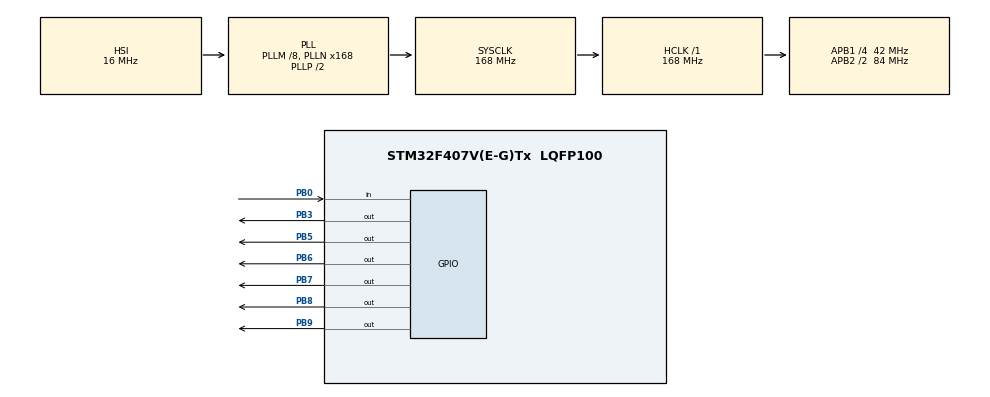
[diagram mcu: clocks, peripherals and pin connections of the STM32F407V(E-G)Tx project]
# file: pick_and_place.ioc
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Mcu.Family=STM32F4
Mcu.Name=STM32F407V(E-G)Tx
Mcu.Package=LQFP100
NVIC.PriorityGroup=NVIC_PRIORITYGROUP_4
PA13.Mode=Serial_Wire
PA13.Signal=SYS_JTMS-SWDIO
PA14.Mode=Serial_Wire
PA14.Signal=SYS_JTCK-SWCLK
PB0.Signal=GPIO_Input
PB3.Signal=GPIO_Output
PB5.Signal=GPIO_Output
PB6.Signal=GPIO_Output
PB7.Signal=GPIO_Output
PB8.Signal=GPIO_Output
PB9.Signal=GPIO_Output
PH0-OSC_IN.Mode=HSE-External-Oscillator
PH0-OSC_IN.Signal=RCC_OSC_IN
PH1-OSC_OUT.Mode=HSE-External-Oscillator
PH1-OSC_OUT.Signal=RCC_OSC_OUT
ProjectManager.HeapSize=0x200
ProjectManager.StackSize=0x400
ProjectManager.TargetToolchain=STM32CubeIDE
RCC.48MHZClocksFreq_Value=84000000
RCC.AHBFreq_Value=168000000
RCC.APB1CLKDivider=RCC_HCLK_DIV4
RCC.APB1Freq_Value=42000000
RCC.APB1TimFreq_Value=84000000
RCC.APB2CLKDivider=RCC_HCLK_DIV2
RCC.APB2Freq_Value=84000000
RCC.APB2TimFreq_Value=168000000
RCC.CortexFreq_Value=168000000
RCC.HCLKFreq_Value=168000000
RCC.HSE_VALUE=25000000
RCC.HSI_VALUE=16000000
RCC.LSE_VALUE=32768
RCC.PLLM=8
RCC.PLLN=168
RCC.SYSCLKFreq_VALUE=168000000
RCC.SYSCLKSource=RCC_SYSCLKSOURCE_PLLCLK
RCC.VCOOutputFreq_Value=336000000
board=custom

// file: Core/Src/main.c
/* USER CODE BEGIN Header */
/**
  ******************************************************************************
  * @file           : main.c
  * @brief          : Main program body
  ******************************************************************************
  * @attention
  *
  * Copyright (c) 2022 STMicroelectronics.
  * All rights reserved.
  *
  * This software is licensed under terms that can be found in the LICENSE file
  * in the root directory of this software component.
  * If no LICENSE file comes with this software, it is provided AS-IS.
  *
  ******************************************************************************
  */
/* USER CODE END Header */
#include "main.h"
#include <stdio.h>
#include <string.h>

/* USER CODE BEGIN Includes */

#define Relay_1_ON HAL_GPIO_WritePin(GPIOB, GPIO_PIN_3, GPIO_PIN_RESET)
#define Relay_1_OFF HAL_GPIO_WritePin(GPIOB, GPIO_PIN_3, GPIO_PIN_SET)

#define Relay_2_ON HAL_GPIO_WritePin(GPIOB, GPIO_PIN_5, GPIO_PIN_RESET)
#define Relay_2_OFF HAL_GPIO_WritePin(GPIOB, GPIO_PIN_5, GPIO_PIN_SET)

#define Relay_3_ON HAL_GPIO_WritePin(GPIOB, GPIO_PIN_6, GPIO_PIN_RESET)
#define Relay_3_OFF HAL_GPIO_WritePin(GPIOB, GPIO_PIN_6, GPIO_PIN_SET)

#define Relay_4_ON HAL_GPIO_WritePin(GPIOB, GPIO_PIN_7, GPIO_PIN_RESET)
#define Relay_4_OFF HAL_GPIO_WritePin(GPIOB, GPIO_PIN_7, GPIO_PIN_SET)

#define SUCTION_ON HAL_GPIO_WritePin(GPIOB, GPIO_PIN_8, GPIO_PIN_RESET)
#define SUCTION_OFF HAL_GPIO_WritePin(GPIOB, GPIO_PIN_8, GPIO_PIN_SET)

/* USER CODE END Includes */

void SystemClock_Config(void);
static void MX_GPIO_Init(void);

void goright()
{
	Relay_1_ON;
	Relay_2_OFF;
}

void goleft()
{
	Relay_1_OFF;
	Relay_2_ON;
}

void go_up()
{
	Relay_3_ON;
	Relay_4_OFF;
}

void go_down()
{
	Relay_3_OFF;
	Relay_4_ON;
}

void initialization()
{
	goright();
	HAL_GPIO_WritePin(GPIOB, GPIO_PIN_9, GPIO_PIN_SET);
	go_up();
	HAL_Delay(5000);
}

void turnoff_init()
{
	Relay_1_OFF;
	Relay_2_OFF;
	Relay_3_OFF;
	Relay_4_OFF;
	HAL_GPIO_WritePin(GPIOB, GPIO_PIN_9, GPIO_PIN_SET);
}

void turnoff(){
	Relay_1_OFF;
	Relay_2_OFF;
	Relay_3_OFF;
	Relay_4_OFF;
}
int main(void)
{

  /* MCU Configuration--------------------------------------------------------*/

  /* Reset of all peripherals, Initializes the Flash interface and the Systick. */
  HAL_Init();

  /* Configure the system clock */
  SystemClock_Config();

  /* Initialize all configured peripherals */
  MX_GPIO_Init();
  /* USER CODE BEGIN 2 */
initialization();
turnoff_init();
  /* USER CODE END 2 */

  /* Infinite loop */
  while (1)
  {

   if ((HAL_GPIO_ReadPin(GPIOB, GPIO_PIN_0)==GPIO_PIN_SET))
   {
	   go_down(); // coming down R3 off, R4 On
	   HAL_Delay(3000);
	   turnoff();
	   HAL_GPIO_WritePin(GPIOB, GPIO_PIN_9, GPIO_PIN_RESET); //suction on
	   go_up(); //Go Up, R3 On, R4 off
	   HAL_Delay(4000);
	   turnoff();
	   goleft();    ///// go left R1 Off, R2 On
	   HAL_Delay(3000);
	   turnoff();
	   HAL_GPIO_WritePin(GPIOB, GPIO_PIN_9, GPIO_PIN_SET);   //suction off
	   HAL_Delay(200);
	   goright();      // Go left R1 On, R2 Off
	   HAL_Delay(2000);
       turnoff();

   }
  }
}

void SystemClock_Config(void)
{
  RCC_OscInitTypeDef RCC_OscInitStruct = {0};
  RCC_ClkInitTypeDef RCC_ClkInitStruct = {0};

  /** Configure the main internal regulator output voltage
  */
  __HAL_RCC_PWR_CLK_ENABLE();
  __HAL_PWR_VOLTAGESCALING_CONFIG(PWR_REGULATOR_VOLTAGE_SCALE1);
  /** Initializes the RCC Oscillators according to the specified parameters
  * in the RCC_OscInitTypeDef structure.
  */
  RCC_OscInitStruct.OscillatorType = RCC_OSCILLATORTYPE_HSI;
  RCC_OscInitStruct.HSIState = RCC_HSI_ON;
  RCC_OscInitStruct.HSICalibrationValue = RCC_HSICALIBRATION_DEFAULT;
  RCC_OscInitStruct.PLL.PLLState = RCC_PLL_ON;
  RCC_OscInitStruct.PLL.PLLSource = RCC_PLLSOURCE_HSI;
  RCC_OscInitStruct.PLL.PLLM = 8;
  RCC_OscInitStruct.PLL.PLLN = 168;
  RCC_OscInitStruct.PLL.PLLP = RCC_PLLP_DIV2;
  RCC_OscInitStruct.PLL.PLLQ = 4;
  if (HAL_RCC_OscConfig(&RCC_OscInitStruct) != HAL_OK)
  {
    Error_Handler();
  }
  /** Initializes the CPU, AHB and APB buses clocks
  */
  RCC_ClkInitStruct.ClockType = RCC_CLOCKTYPE_HCLK|RCC_CLOCKTYPE_SYSCLK
                              |RCC_CLOCKTYPE_PCLK1|RCC_CLOCKTYPE_PCLK2;
  RCC_ClkInitStruct.SYSCLKSource = RCC_SYSCLKSOURCE_PLLCLK;
  RCC_ClkInitStruct.AHBCLKDivider = RCC_SYSCLK_DIV1;
  RCC_ClkInitStruct.APB1CLKDivider = RCC_HCLK_DIV4;
  RCC_ClkInitStruct.APB2CLKDivider = RCC_HCLK_DIV2;

  if (HAL_RCC_ClockConfig(&RCC_ClkInitStruct, FLASH_LATENCY_5) != HAL_OK)
  {
    Error_Handler();
  }
}

static void MX_GPIO_Init(void)
{
  GPIO_InitTypeDef GPIO_InitStruct = {0};

  /* GPIO Ports Clock Enable */
  __HAL_RCC_GPIOH_CLK_ENABLE();
  __HAL_RCC_GPIOB_CLK_ENABLE();
  __HAL_RCC_GPIOA_CLK_ENABLE();

  /*Configure GPIO pin Output Level */
  HAL_GPIO_WritePin(GPIOB, GPIO_PIN_3|GPIO_PIN_5|GPIO_PIN_6|GPIO_PIN_7
                          |GPIO_PIN_8|GPIO_PIN_9, GPIO_PIN_RESET);

  /*Configure GPIO pin : PB0 */
  GPIO_InitStruct.Pin = GPIO_PIN_0;
  GPIO_InitStruct.Mode = GPIO_MODE_INPUT;
  GPIO_InitStruct.Pull = GPIO_NOPULL;
  HAL_GPIO_Init(GPIOB, &GPIO_InitStruct);

  /*Configure GPIO pins : PB3 PB5 PB6 PB7
                           PB8 PB9 */
  GPIO_InitStruct.Pin = GPIO_PIN_3|GPIO_PIN_5|GPIO_PIN_6|GPIO_PIN_7
                          |GPIO_PIN_8|GPIO_PIN_9;
  GPIO_InitStruct.Mode = GPIO_MODE_OUTPUT_PP;
  GPIO_InitStruct.Pull = GPIO_NOPULL;
  GPIO_InitStruct.Speed = GPIO_SPEED_FREQ_LOW;
  HAL_GPIO_Init(GPIOB, &GPIO_InitStruct);

}

void Error_Handler(void)
{
  __disable_irq();
  while (1)
  {
  }
}
